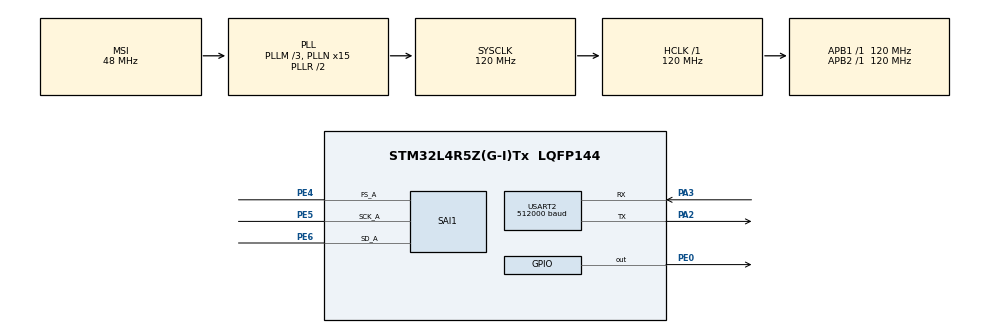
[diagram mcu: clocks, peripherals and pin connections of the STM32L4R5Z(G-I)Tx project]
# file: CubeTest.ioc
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Mcu.Family=STM32L4
Mcu.Name=STM32L4R5Z(G-I)Tx
Mcu.Package=LQFP144
NVIC.PriorityGroup=NVIC_PRIORITYGROUP_4
NVIC.TIM6_DAC_IRQn=true\:0\:0\:false\:false\:true\:true\:true\:true
PA2.Mode=Asynchronous
PA2.Signal=USART2_TX
PA3.Mode=Asynchronous
PA3.Signal=USART2_RX
PE0.Signal=GPIO_Output
PE4.Mode=SAI_A_Master
PE4.Signal=SAI1_FS_A
PE5.Mode=SAI_A_Master
PE5.Signal=SAI1_SCK_A
PE6.Mode=SAI_A_Master
PE6.Signal=SAI1_SD_A
ProjectManager.HeapSize=0x200
ProjectManager.StackSize=0x400
ProjectManager.TargetToolchain=Makefile
RCC.ADCFreq_Value=48000000
RCC.AHBFreq_Value=120000000
RCC.APB1Freq_Value=120000000
RCC.APB1TimFreq_Value=120000000
RCC.APB2Freq_Value=120000000
RCC.APB2TimFreq_Value=120000000
RCC.CortexFreq_Value=120000000
RCC.HCLKFreq_Value=120000000
RCC.HSE_VALUE=8000000
RCC.HSI48_VALUE=48000000
RCC.HSI_VALUE=16000000
RCC.LSE_VALUE=32768
RCC.MSIClockRange=RCC_MSIRANGE_11
RCC.MSI_VALUE=48000000
RCC.PLLM1=3
RCC.PLLM2=16
RCC.PLLN=15
RCC.PLLP=RCC_PLLP_DIV30
RCC.PLLSAI1N=32
RCC.PLLSAI1P=RCC_PLLP_DIV6
RCC.SYSCLKFreq_VALUE=120000000
RCC.SYSCLKSource=RCC_SYSCLKSOURCE_PLLCLK
RCC.USBFreq_Value=48000000
RCC.VCOOutputFreq_Value=240000000
SAI1.AudioFrequency-SAI_A_Master=SAI_AUDIO_FREQUENCY_MCKDIV
SAI1.AudioMode-SAI_A_Master=SAI_MODEMASTER_RX
SAI1.BasicDataSize-SAI_A_Master=SAI_PROTOCOL_DATASIZE_32BIT
SAI1.ErrorAudioFreq-SAI_A_Master=-91.86 %
SAI1.InitProtocol-SAI_A_Master=Enable
SAI1.Instance-SAI_A_Master=SAI$Index_Block_A
SAI1.MClockEnable-SAI_A_Master=SAI_MASTERCLOCK_DISABLE
SAI1.MckOverSampling-SAI_A_Master=SAI_MCK_OVERSAMPLING_DISABLE
SAI1.MonoStereoMode-SAI_A_Master=SAI_MONOMODE
SAI1.RealAudioFreq-SAI_A_Master=62.5 KHz
SAI1.VirtualMode-SAI_A_Master=VM_MASTER
SAI1.VirtualProtocol-SAI_A_BASIC=VM_BASIC_PROTOCOL
TIM6.AutoReloadPreload=TIM_AUTORELOAD_PRELOAD_ENABLE
TIM6.Period=1
TIM6.Prescaler=1880
USART2.BaudRate=512000
USART2.VirtualMode-Asynchronous=VM_ASYNC
VP_SAI1_VP_$IpInstance_SAIA_SAI_BASIC.Mode=SAI_A_BASIC
VP_TIM6_VS_ClockSourceINT.Mode=Enable_Timer
board=NUCLEO-L4R5ZI

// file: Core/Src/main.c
/* USER CODE BEGIN Header */
/**
 ******************************************************************************
 * @file           : main.c
 * @brief          : Main program body
 ******************************************************************************
 * @attention
 *
 * Copyright (c) 2023 STMicroelectronics.
 * All rights reserved.
 *
 * This software is licensed under terms that can be found in the LICENSE file
 * in the root directory of this software component.
 * If no LICENSE file comes with this software, it is provided AS-IS.
 *
 ******************************************************************************
 */
/* USER CODE END Header */
#include "main.h"

SAI_HandleTypeDef hsai_BlockA1;

TIM_HandleTypeDef htim6;

UART_HandleTypeDef huart2;

void SystemClock_Config(void);
static void MX_GPIO_Init(void);
static void MX_USART2_UART_Init(void);
static void MX_SAI1_Init(void);
static void MX_TIM6_Init(void);

/* USER CODE BEGIN 0 */
uint8_t i2sData[4] = {0};
uint8_t dataToWrite[2] = {0};
/* USER CODE END 0 */

int main(void) {

    /* MCU Configuration--------------------------------------------------------*/

    /* Reset of all peripherals, Initializes the Flash interface and the Systick. */
    HAL_Init();

    /* Configure the system clock */
    SystemClock_Config();

    /* Initialize all configured peripherals */
    MX_GPIO_Init();
    MX_USART2_UART_Init();
    MX_SAI1_Init();
    MX_TIM6_Init();
    /* USER CODE BEGIN 2 */
    HAL_TIM_Base_Start_IT(&htim6);
    /* USER CODE END 2 */

    /* Infinite loop */
    while (1) {

    }
}

void SystemClock_Config(void) {
    RCC_OscInitTypeDef RCC_OscInitStruct = {0};
    RCC_ClkInitTypeDef RCC_ClkInitStruct = {0};

    /** Configure the main internal regulator output voltage
     */
    if (HAL_PWREx_ControlVoltageScaling(PWR_REGULATOR_VOLTAGE_SCALE1_BOOST) != HAL_OK) {
        Error_Handler();
    }

    /** Initializes the RCC Oscillators according to the specified parameters
     * in the RCC_OscInitTypeDef structure.
     */
    RCC_OscInitStruct.OscillatorType = RCC_OSCILLATORTYPE_MSI;
    RCC_OscInitStruct.MSIState = RCC_MSI_ON;
    RCC_OscInitStruct.MSICalibrationValue = 0;
    RCC_OscInitStruct.MSIClockRange = RCC_MSIRANGE_11;
    RCC_OscInitStruct.PLL.PLLState = RCC_PLL_ON;
    RCC_OscInitStruct.PLL.PLLSource = RCC_PLLSOURCE_MSI;
    RCC_OscInitStruct.PLL.PLLM = 3;
    RCC_OscInitStruct.PLL.PLLN = 15;
    RCC_OscInitStruct.PLL.PLLP = RCC_PLLP_DIV30;
    RCC_OscInitStruct.PLL.PLLQ = RCC_PLLQ_DIV2;
    RCC_OscInitStruct.PLL.PLLR = RCC_PLLR_DIV2;
    if (HAL_RCC_OscConfig(&RCC_OscInitStruct) != HAL_OK) {
        Error_Handler();
    }

    /** Initializes the CPU, AHB and APB buses clocks
     */
    RCC_ClkInitStruct.ClockType = RCC_CLOCKTYPE_HCLK | RCC_CLOCKTYPE_SYSCLK | RCC_CLOCKTYPE_PCLK1 | RCC_CLOCKTYPE_PCLK2;
    RCC_ClkInitStruct.SYSCLKSource = RCC_SYSCLKSOURCE_PLLCLK;
    RCC_ClkInitStruct.AHBCLKDivider = RCC_SYSCLK_DIV1;
    RCC_ClkInitStruct.APB1CLKDivider = RCC_HCLK_DIV1;
    RCC_ClkInitStruct.APB2CLKDivider = RCC_HCLK_DIV1;

    if (HAL_RCC_ClockConfig(&RCC_ClkInitStruct, FLASH_LATENCY_5) != HAL_OK) {
        Error_Handler();
    }
}

static void MX_SAI1_Init(void) {

    hsai_BlockA1.Instance = SAI1_Block_A;
    hsai_BlockA1.Init.AudioMode = SAI_MODEMASTER_RX;
    hsai_BlockA1.Init.Synchro = SAI_ASYNCHRONOUS;
    hsai_BlockA1.Init.OutputDrive = SAI_OUTPUTDRIVE_DISABLE;
    hsai_BlockA1.Init.NoDivider = SAI_MASTERDIVIDER_ENABLE;
    hsai_BlockA1.Init.FIFOThreshold = SAI_FIFOTHRESHOLD_EMPTY;
    hsai_BlockA1.Init.AudioFrequency = SAI_AUDIO_FREQUENCY_MCKDIV;
    hsai_BlockA1.Init.Mckdiv = 0;
    hsai_BlockA1.Init.SynchroExt = SAI_SYNCEXT_DISABLE;
    hsai_BlockA1.Init.MonoStereoMode = SAI_MONOMODE;
    hsai_BlockA1.Init.CompandingMode = SAI_NOCOMPANDING;
    if (HAL_SAI_InitProtocol(&hsai_BlockA1, SAI_I2S_STANDARD, SAI_PROTOCOL_DATASIZE_32BIT, 2) != HAL_OK) {
        Error_Handler();
    }
}

static void MX_TIM6_Init(void) {

    TIM_MasterConfigTypeDef sMasterConfig = {0};

    htim6.Instance = TIM6;
    htim6.Init.Prescaler = 1880;
    htim6.Init.CounterMode = TIM_COUNTERMODE_UP;
    htim6.Init.Period = 1;
    htim6.Init.AutoReloadPreload = TIM_AUTORELOAD_PRELOAD_ENABLE;
    if (HAL_TIM_Base_Init(&htim6) != HAL_OK) {
        Error_Handler();
    }
    sMasterConfig.MasterOutputTrigger = TIM_TRGO_RESET;
    sMasterConfig.MasterSlaveMode = TIM_MASTERSLAVEMODE_DISABLE;
    if (HAL_TIMEx_MasterConfigSynchronization(&htim6, &sMasterConfig) != HAL_OK) {
        Error_Handler();
    }
}

static void MX_USART2_UART_Init(void) {

    huart2.Instance = USART2;
    huart2.Init.BaudRate = 921600;
    huart2.Init.WordLength = UART_WORDLENGTH_8B;
    huart2.Init.StopBits = UART_STOPBITS_1;
    huart2.Init.Parity = UART_PARITY_NONE;
    huart2.Init.Mode = UART_MODE_TX_RX;
    huart2.Init.HwFlowCtl = UART_HWCONTROL_NONE;
    huart2.Init.OverSampling = UART_OVERSAMPLING_16;
    huart2.Init.OneBitSampling = UART_ONE_BIT_SAMPLE_DISABLE;
    huart2.Init.ClockPrescaler = UART_PRESCALER_DIV1;
    huart2.AdvancedInit.AdvFeatureInit = UART_ADVFEATURE_NO_INIT;
    if (HAL_UART_Init(&huart2) != HAL_OK) {
        Error_Handler();
    }
    if (HAL_UARTEx_SetTxFifoThreshold(&huart2, UART_TXFIFO_THRESHOLD_1_8) != HAL_OK) {
        Error_Handler();
    }
    if (HAL_UARTEx_SetRxFifoThreshold(&huart2, UART_RXFIFO_THRESHOLD_1_8) != HAL_OK) {
        Error_Handler();
    }
    if (HAL_UARTEx_DisableFifoMode(&huart2) != HAL_OK) {
        Error_Handler();
    }
}

static void MX_GPIO_Init(void) {
    GPIO_InitTypeDef GPIO_InitStruct = {0};

    /* GPIO Ports Clock Enable */
    __HAL_RCC_GPIOE_CLK_ENABLE();
    __HAL_RCC_GPIOA_CLK_ENABLE();

    /*Configure GPIO pin Output Level */
    HAL_GPIO_WritePin(GPIOE, GPIO_PIN_0, GPIO_PIN_RESET);

    /*Configure GPIO pin : PE0 */
    GPIO_InitStruct.Pin = GPIO_PIN_0;
    GPIO_InitStruct.Mode = GPIO_MODE_OUTPUT_PP;
    GPIO_InitStruct.Pull = GPIO_NOPULL;
    GPIO_InitStruct.Speed = GPIO_SPEED_FREQ_LOW;
    HAL_GPIO_Init(GPIOE, &GPIO_InitStruct);

}

/* USER CODE BEGIN 4 */
void TimerHandler(void) {
    if (__HAL_TIM_GET_FLAG(&htim6, TIM_FLAG_UPDATE) != RESET) {
        if (__HAL_TIM_GET_IT_SOURCE(&htim6, TIM_IT_UPDATE) != RESET) {
            __HAL_TIM_CLEAR_FLAG(&htim6, TIM_FLAG_UPDATE);

            if (HAL_SAI_Receive(&hsai_BlockA1, i2sData, 4, HAL_MAX_DELAY) == HAL_OK) {
                dataToWrite[1] = i2sData[3];
                dataToWrite[0] = i2sData[2];

                HAL_UART_Transmit(&huart2, (uint8_t *)(&dataToWrite), 2, HAL_MAX_DELAY);
            }
        }
    }
}
/* USER CODE END 4 */

void Error_Handler(void) {
    __disable_irq();
    while (1) {
    }
}
